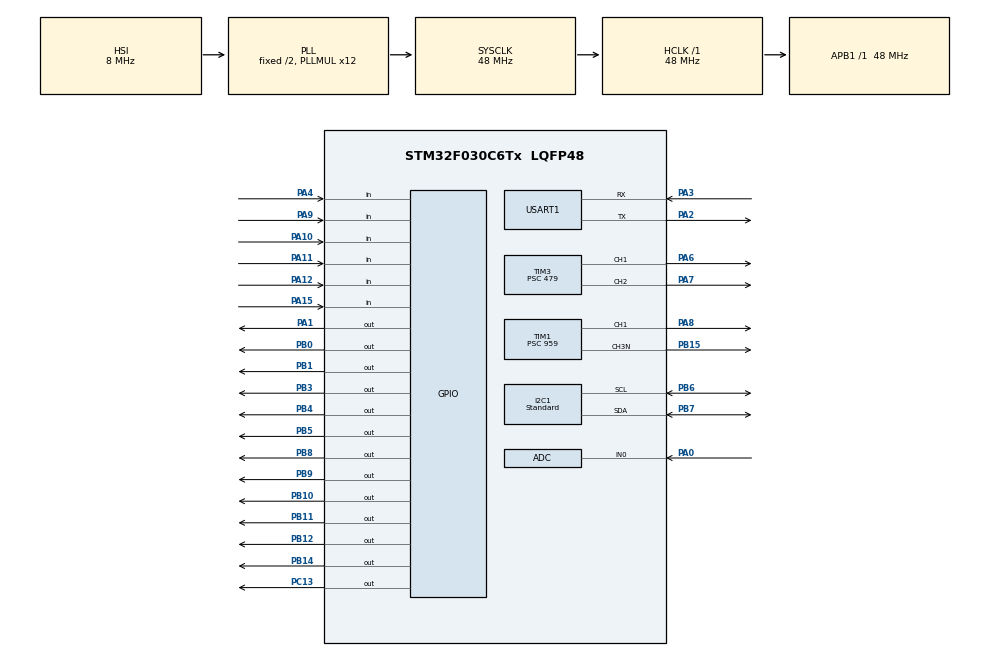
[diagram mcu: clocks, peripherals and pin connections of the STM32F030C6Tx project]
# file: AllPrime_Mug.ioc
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ADC.ClockPrescaler=ADC_CLOCK_ASYNC_DIV1
ADC.ContinuousConvMode=DISABLE
ADC.DiscontinuousConvMode=DISABLE
ADC.EOCSelection=ADC_EOC_SINGLE_CONV
I2C1.I2C_Fall_Time=0
I2C1.I2C_Rise_Time=0
I2C1.I2C_Speed_Mode=I2C_Standard
Mcu.Family=STM32F0
Mcu.Name=STM32F030C6Tx
Mcu.Package=LQFP48
NVIC.TIM14_IRQn=true\:3\:0\:true\:false\:true\:true\:true\:true
NVIC.TIM16_IRQn=true\:1\:0\:true\:false\:true\:true\:true\:true
NVIC.USART1_IRQn=true\:0\:0\:false\:false\:true\:true\:true\:true
PA0.Mode=IN0
PA0.Signal=ADC_IN0
PA1.Signal=GPIO_Output
PA10.Signal=GPIO_Input
PA11.Signal=GPIO_Input
PA12.Signal=GPIO_Input
PA13.Mode=Serial_Wire
PA13.Signal=SYS_SWDIO
PA14.Mode=Serial_Wire
PA14.Signal=SYS_SWCLK
PA15.Signal=GPIO_Input
PA2.Mode=Asynchronous
PA2.Signal=USART1_TX
PA3.Mode=Asynchronous
PA3.Signal=USART1_RX
PA4.Signal=GPIO_Input
PA6.Signal=S_TIM3_CH1
PA7.Signal=S_TIM3_CH2
PA8.Signal=S_TIM1_CH1
PA9.Signal=GPIO_Input
PB0.Signal=GPIO_Output
PB1.Signal=GPIO_Output
PB10.Signal=GPIO_Output
PB11.Signal=GPIO_Output
PB12.Signal=GPIO_Output
PB14.Signal=GPIO_Output
PB15.Mode=PWM Generation3 CH3N
PB15.Signal=TIM1_CH3N
PB3.Signal=GPIO_Output
PB4.Signal=GPIO_Output
PB5.Signal=GPIO_Output
PB6.GPIO_Pu=GPIO_NOPULL
PB6.Mode=I2C
PB6.Signal=I2C1_SCL
PB7.GPIO_Pu=GPIO_PULLUP
PB7.Mode=I2C
PB7.Signal=I2C1_SDA
PB8.Signal=GPIO_Output
PB9.Signal=GPIO_Output
PC13.Signal=GPIO_Output
PC14-OSC32_IN.Mode=LSE-External-Oscillator
PC14-OSC32_IN.Signal=RCC_OSC32_IN
PC15-OSC32_OUT.Mode=LSE-External-Oscillator
PC15-OSC32_OUT.Signal=RCC_OSC32_OUT
PF0-OSC_IN.Mode=HSE-External-Oscillator
PF0-OSC_IN.Signal=RCC_OSC_IN
PF1-OSC_OUT.Mode=HSE-External-Oscillator
PF1-OSC_OUT.Signal=RCC_OSC_OUT
ProjectManager.HeapSize=0x200
ProjectManager.StackSize=0x400
ProjectManager.TargetToolchain=Makefile
RCC.AHBFreq_Value=48000000
RCC.APB1Freq_Value=48000000
RCC.APB1TimFreq_Value=48000000
RCC.HCLKFreq_Value=48000000
RCC.PLLMUL=RCC_PLL_MUL12
RCC.SYSCLKFreq_VALUE=48000000
RCC.SYSCLKSource=RCC_SYSCLKSOURCE_PLLCLK
SH.S_TIM1_CH1.0=TIM1_CH1,PWM Generation1 CH1
SH.S_TIM3_CH1.0=TIM3_CH1,PWM Generation1 CH1
SH.S_TIM3_CH2.0=TIM3_CH2,PWM Generation2 CH2
TIM1.AutoReloadPreload=TIM_AUTORELOAD_PRELOAD_ENABLE
TIM1.Channel-PWM\ Generation1\ CH1=TIM_CHANNEL_1
TIM1.Channel-PWM\ Generation3\ CH3N=TIM_CHANNEL_3
TIM1.Period=1000
TIM1.Prescaler=959
TIM14.AutoReloadPreload=TIM_AUTORELOAD_PRELOAD_ENABLE
TIM14.Period=1000
TIM14.Prescaler=479
TIM16.AutoReloadPreload=TIM_AUTORELOAD_PRELOAD_ENABLE
TIM16.ClockDivision=TIM_CLOCKDIVISION_DIV1
TIM16.Period=100
TIM16.Prescaler=47
TIM3.Channel-PWM\ Generation1\ CH1=TIM_CHANNEL_1
TIM3.Channel-PWM\ Generation2\ CH2=TIM_CHANNEL_2
TIM3.Period=1000
TIM3.Prescaler=479
USART1.VirtualMode-Asynchronous=VM_ASYNC
VP_ADC_TempSens_Input.Mode=IN-TempSens
VP_TIM14_VS_ClockSourceINT.Mode=Enable_Timer
VP_TIM16_VS_ClockSourceINT.Mode=Enable_Timer
VP_TIM1_VS_ClockSourceINT.Mode=Internal
VP_TIM3_VS_ClockSourceINT.Mode=Internal
board=custom

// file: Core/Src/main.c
/* USER CODE BEGIN Header */
/**
  ******************************************************************************
  * @file           : main.c
  * @brief          : Main program body
  ******************************************************************************
  * @attention
  *
  * <h2><center>&copy; Copyright (c) 2021 STMicroelectronics.
  * All rights reserved.</center></h2>
  *
  * This software component is licensed by ST under BSD 3-Clause license,
  * the "License"; You may not use this file except in compliance with the
  * License. You may obtain a copy of the License at:
  *                        opensource.org/licenses/BSD-3-Clause
  *
  ******************************************************************************
  */
/* USER CODE END Header */
#include "main.h"
#include "os.h"

ADC_HandleTypeDef hadc;

I2C_HandleTypeDef hi2c1;

TIM_HandleTypeDef htim1;
TIM_HandleTypeDef htim3;
TIM_HandleTypeDef htim14;
TIM_HandleTypeDef htim16;

UART_HandleTypeDef huart1;

void SystemClock_Config(void);
static void MX_GPIO_Init(void);
static void MX_ADC_Init(void);
static void MX_TIM16_Init(void);
static void MX_I2C1_Init(void);
static void MX_TIM1_Init(void);
static void MX_TIM14_Init(void);
static void MX_TIM3_Init(void);
static void MX_USART1_UART_Init(void);

int main(void)
{

    /* MCU Configuration--------------------------------------------------------*/

    /* Reset of all peripherals, Initializes the Flash interface and the Systick. */
    HAL_Init();

    /* Configure the system clock */
    SystemClock_Config();

    /* Initialize all configured peripherals */
    MX_GPIO_Init();
    MX_ADC_Init();
    MX_TIM16_Init();
 	  MX_I2C1_Init();
 	  MX_TIM1_Init();
  	MX_TIM14_Init();
    MX_TIM3_Init();
    MX_USART1_UART_Init();
    /* USER CODE BEGIN 2 */
    HAL_TIM_Base_Start_IT(&htim1);
    HAL_TIM_Base_Start_IT(&htim3);
    HAL_TIM_Base_Start_IT(&htim14);
    HAL_TIM_Base_Start_IT(&htim16);
    HAL_Delay(1000);
	  Os_Init_Task();
    HAL_TIM_PWM_Start(&htim3,TIM_CHANNEL_1);
    HAL_TIM_PWM_Start(&htim3,TIM_CHANNEL_2);
    HAL_TIM_PWM_Start(&htim1,TIM_CHANNEL_1);
    HAL_TIMEx_PWMN_Start(&htim1,TIM_CHANNEL_3);
    /* USER CODE END 2 */
    /* Infinite loop */

    /* USER CODE BEGIN WHILE */
    while (1)
    {
        Os_Handler();
    }
    /* USER CODE END 3 */
}

void SystemClock_Config(void)
{
  RCC_OscInitTypeDef RCC_OscInitStruct = {0};
  RCC_ClkInitTypeDef RCC_ClkInitStruct = {0};
  RCC_PeriphCLKInitTypeDef PeriphClkInit = {0};

  /** Initializes the RCC Oscillators according to the specified parameters
  * in the RCC_OscInitTypeDef structure.
  */
  RCC_OscInitStruct.OscillatorType = RCC_OSCILLATORTYPE_HSI|RCC_OSCILLATORTYPE_HSI14;
  RCC_OscInitStruct.HSIState = RCC_HSI_ON;
  RCC_OscInitStruct.HSI14State = RCC_HSI14_ON;
  RCC_OscInitStruct.HSICalibrationValue = RCC_HSICALIBRATION_DEFAULT;
  RCC_OscInitStruct.HSI14CalibrationValue = 16;
  RCC_OscInitStruct.PLL.PLLState = RCC_PLL_ON;
  RCC_OscInitStruct.PLL.PLLSource = RCC_PLLSOURCE_HSI;
  RCC_OscInitStruct.PLL.PLLMUL = RCC_PLL_MUL12;
  RCC_OscInitStruct.PLL.PREDIV = RCC_PREDIV_DIV1;
  if (HAL_RCC_OscConfig(&RCC_OscInitStruct) != HAL_OK)
  {
    Error_Handler();
  }

  /** Initializes the CPU, AHB and APB buses clocks
  */
  RCC_ClkInitStruct.ClockType = RCC_CLOCKTYPE_HCLK|RCC_CLOCKTYPE_SYSCLK
                              |RCC_CLOCKTYPE_PCLK1;
  RCC_ClkInitStruct.SYSCLKSource = RCC_SYSCLKSOURCE_PLLCLK;
  RCC_ClkInitStruct.AHBCLKDivider = RCC_SYSCLK_DIV1;
  RCC_ClkInitStruct.APB1CLKDivider = RCC_HCLK_DIV1;

  if (HAL_RCC_ClockConfig(&RCC_ClkInitStruct, FLASH_LATENCY_1) != HAL_OK)
  {
    Error_Handler();
  }
  PeriphClkInit.PeriphClockSelection = RCC_PERIPHCLK_USART1|RCC_PERIPHCLK_I2C1;
  PeriphClkInit.Usart1ClockSelection = RCC_USART1CLKSOURCE_PCLK1;
  PeriphClkInit.I2c1ClockSelection = RCC_I2C1CLKSOURCE_HSI;
  if (HAL_RCCEx_PeriphCLKConfig(&PeriphClkInit) != HAL_OK)
  {
    Error_Handler();
  }
}

static void MX_ADC_Init(void)
{

  ADC_ChannelConfTypeDef sConfig = {0};

  /** Configure the global features of the ADC (Clock, Resolution, Data Alignment and number of conversion)
  */
  hadc.Instance = ADC1;
  hadc.Init.ClockPrescaler = ADC_CLOCK_ASYNC_DIV1;
  hadc.Init.Resolution = ADC_RESOLUTION_12B;
  hadc.Init.DataAlign = ADC_DATAALIGN_RIGHT;
  hadc.Init.ScanConvMode = ADC_SCAN_DIRECTION_FORWARD;
  hadc.Init.EOCSelection = ADC_EOC_SINGLE_CONV;
  hadc.Init.LowPowerAutoWait = DISABLE;
  hadc.Init.LowPowerAutoPowerOff = DISABLE;
  hadc.Init.ContinuousConvMode = DISABLE;
  hadc.Init.DiscontinuousConvMode = DISABLE;
  hadc.Init.ExternalTrigConv = ADC_SOFTWARE_START;
  hadc.Init.ExternalTrigConvEdge = ADC_EXTERNALTRIGCONVEDGE_NONE;
  hadc.Init.DMAContinuousRequests = DISABLE;
  hadc.Init.Overrun = ADC_OVR_DATA_PRESERVED;
  if (HAL_ADC_Init(&hadc) != HAL_OK)
  {
    Error_Handler();
  }

  /** Configure for the selected ADC regular channel to be converted.
  */
  sConfig.Channel = ADC_CHANNEL_0;
  sConfig.Rank = ADC_RANK_CHANNEL_NUMBER;
  sConfig.SamplingTime = ADC_SAMPLETIME_1CYCLE_5;
  if (HAL_ADC_ConfigChannel(&hadc, &sConfig) != HAL_OK)
  {
    Error_Handler();
  }

  /** Configure for the selected ADC regular channel to be converted.
  */
  sConfig.Channel = ADC_CHANNEL_TEMPSENSOR;
  if (HAL_ADC_ConfigChannel(&hadc, &sConfig) != HAL_OK)
  {
    Error_Handler();
  }

}

static void MX_I2C1_Init(void)
{

  hi2c1.Instance = I2C1;
  hi2c1.Init.Timing = 0x2000090E;
  hi2c1.Init.OwnAddress1 = 0;
  hi2c1.Init.AddressingMode = I2C_ADDRESSINGMODE_7BIT;
  hi2c1.Init.DualAddressMode = I2C_DUALADDRESS_DISABLE;
  hi2c1.Init.OwnAddress2 = 0;
  hi2c1.Init.OwnAddress2Masks = I2C_OA2_NOMASK;
  hi2c1.Init.GeneralCallMode = I2C_GENERALCALL_DISABLE;
  hi2c1.Init.NoStretchMode = I2C_NOSTRETCH_DISABLE;
  if (HAL_I2C_Init(&hi2c1) != HAL_OK)
  {
    Error_Handler();
  }

  /** Configure Analogue filter
  */
  if (HAL_I2CEx_ConfigAnalogFilter(&hi2c1, I2C_ANALOGFILTER_ENABLE) != HAL_OK)
  {
    Error_Handler();
  }

  /** Configure Digital filter
  */
  if (HAL_I2CEx_ConfigDigitalFilter(&hi2c1, 0) != HAL_OK)
  {
    Error_Handler();
  }

}

static void MX_TIM1_Init(void)
{

  TIM_ClockConfigTypeDef sClockSourceConfig = {0};
  TIM_MasterConfigTypeDef sMasterConfig = {0};
  TIM_OC_InitTypeDef sConfigOC = {0};
  TIM_BreakDeadTimeConfigTypeDef sBreakDeadTimeConfig = {0};

  htim1.Instance = TIM1;
  htim1.Init.Prescaler = 959;
  htim1.Init.CounterMode = TIM_COUNTERMODE_UP;
  htim1.Init.Period = 1000;
  htim1.Init.ClockDivision = TIM_CLOCKDIVISION_DIV1;
  htim1.Init.RepetitionCounter = 0;
  htim1.Init.AutoReloadPreload = TIM_AUTORELOAD_PRELOAD_ENABLE;
  if (HAL_TIM_Base_Init(&htim1) != HAL_OK)
  {
    Error_Handler();
  }
  sClockSourceConfig.ClockSource = TIM_CLOCKSOURCE_INTERNAL;
  if (HAL_TIM_ConfigClockSource(&htim1, &sClockSourceConfig) != HAL_OK)
  {
    Error_Handler();
  }
  if (HAL_TIM_PWM_Init(&htim1) != HAL_OK)
  {
    Error_Handler();
  }
  sMasterConfig.MasterOutputTrigger = TIM_TRGO_RESET;
  sMasterConfig.MasterSlaveMode = TIM_MASTERSLAVEMODE_DISABLE;
  if (HAL_TIMEx_MasterConfigSynchronization(&htim1, &sMasterConfig) != HAL_OK)
  {
    Error_Handler();
  }
  sConfigOC.OCMode = TIM_OCMODE_PWM1;
  sConfigOC.Pulse = 0;
  sConfigOC.OCPolarity = TIM_OCPOLARITY_HIGH;
  sConfigOC.OCNPolarity = TIM_OCNPOLARITY_HIGH;
  sConfigOC.OCFastMode = TIM_OCFAST_DISABLE;
  sConfigOC.OCIdleState = TIM_OCIDLESTATE_RESET;
  sConfigOC.OCNIdleState = TIM_OCNIDLESTATE_RESET;
  if (HAL_TIM_PWM_ConfigChannel(&htim1, &sConfigOC, TIM_CHANNEL_1) != HAL_OK)
  {
    Error_Handler();
  }
  if (HAL_TIM_PWM_ConfigChannel(&htim1, &sConfigOC, TIM_CHANNEL_3) != HAL_OK)
  {
    Error_Handler();
  }
  sBreakDeadTimeConfig.OffStateRunMode = TIM_OSSR_DISABLE;
  sBreakDeadTimeConfig.OffStateIDLEMode = TIM_OSSI_DISABLE;
  sBreakDeadTimeConfig.LockLevel = TIM_LOCKLEVEL_OFF;
  sBreakDeadTimeConfig.DeadTime = 0;
  sBreakDeadTimeConfig.BreakState = TIM_BREAK_DISABLE;
  sBreakDeadTimeConfig.BreakPolarity = TIM_BREAKPOLARITY_HIGH;
  sBreakDeadTimeConfig.AutomaticOutput = TIM_AUTOMATICOUTPUT_DISABLE;
  if (HAL_TIMEx_ConfigBreakDeadTime(&htim1, &sBreakDeadTimeConfig) != HAL_OK)
  {
    Error_Handler();
  }
  HAL_TIM_MspPostInit(&htim1);

}

static void MX_TIM3_Init(void)
{

  TIM_ClockConfigTypeDef sClockSourceConfig = {0};
  TIM_MasterConfigTypeDef sMasterConfig = {0};
  TIM_OC_InitTypeDef sConfigOC = {0};

  htim3.Instance = TIM3;
  htim3.Init.Prescaler = 479;
  htim3.Init.CounterMode = TIM_COUNTERMODE_UP;
  htim3.Init.Period = 1000;
  htim3.Init.ClockDivision = TIM_CLOCKDIVISION_DIV1;
  htim3.Init.AutoReloadPreload = TIM_AUTORELOAD_PRELOAD_DISABLE;
  if (HAL_TIM_Base_Init(&htim3) != HAL_OK)
  {
    Error_Handler();
  }
  sClockSourceConfig.ClockSource = TIM_CLOCKSOURCE_INTERNAL;
  if (HAL_TIM_ConfigClockSource(&htim3, &sClockSourceConfig) != HAL_OK)
  {
    Error_Handler();
  }
  if (HAL_TIM_PWM_Init(&htim3) != HAL_OK)
  {
    Error_Handler();
  }
  sMasterConfig.MasterOutputTrigger = TIM_TRGO_RESET;
  sMasterConfig.MasterSlaveMode = TIM_MASTERSLAVEMODE_DISABLE;
  if (HAL_TIMEx_MasterConfigSynchronization(&htim3, &sMasterConfig) != HAL_OK)
  {
    Error_Handler();
  }
  sConfigOC.OCMode = TIM_OCMODE_PWM1;
  sConfigOC.Pulse = 0;
  sConfigOC.OCPolarity = TIM_OCPOLARITY_HIGH;
  sConfigOC.OCFastMode = TIM_OCFAST_DISABLE;
  if (HAL_TIM_PWM_ConfigChannel(&htim3, &sConfigOC, TIM_CHANNEL_1) != HAL_OK)
  {
    Error_Handler();
  }
  if (HAL_TIM_PWM_ConfigChannel(&htim3, &sConfigOC, TIM_CHANNEL_2) != HAL_OK)
  {
    Error_Handler();
  }
  HAL_TIM_MspPostInit(&htim3);

}

static void MX_TIM14_Init(void)
{

  htim14.Instance = TIM14;
  htim14.Init.Prescaler = 479;
  htim14.Init.CounterMode = TIM_COUNTERMODE_UP;
  htim14.Init.Period = 1000;
  htim14.Init.ClockDivision = TIM_CLOCKDIVISION_DIV1;
  htim14.Init.AutoReloadPreload = TIM_AUTORELOAD_PRELOAD_ENABLE;
  if (HAL_TIM_Base_Init(&htim14) != HAL_OK)
  {
    Error_Handler();
  }

}

static void MX_TIM16_Init(void)
{

  htim16.Instance = TIM16;
  htim16.Init.Prescaler = 47;
  htim16.Init.CounterMode = TIM_COUNTERMODE_UP;
  htim16.Init.Period = 100;
  htim16.Init.ClockDivision = TIM_CLOCKDIVISION_DIV1;
  htim16.Init.RepetitionCounter = 0;
  htim16.Init.AutoReloadPreload = TIM_AUTORELOAD_PRELOAD_ENABLE;
  if (HAL_TIM_Base_Init(&htim16) != HAL_OK)
  {
    Error_Handler();
  }

}

static void MX_USART1_UART_Init(void)
{

  huart1.Instance = USART1;
  huart1.Init.BaudRate = 38400;
  huart1.Init.WordLength = UART_WORDLENGTH_8B;
  huart1.Init.StopBits = UART_STOPBITS_1;
  huart1.Init.Parity = UART_PARITY_NONE;
  huart1.Init.Mode = UART_MODE_TX_RX;
  huart1.Init.HwFlowCtl = UART_HWCONTROL_NONE;
  huart1.Init.OverSampling = UART_OVERSAMPLING_16;
  huart1.Init.OneBitSampling = UART_ONE_BIT_SAMPLE_DISABLE;
  huart1.AdvancedInit.AdvFeatureInit = UART_ADVFEATURE_NO_INIT;
  if (HAL_UART_Init(&huart1) != HAL_OK)
  {
    Error_Handler();
  }

}

static void MX_GPIO_Init(void)
{
  GPIO_InitTypeDef GPIO_InitStruct = {0};

  /* GPIO Ports Clock Enable */
  __HAL_RCC_GPIOC_CLK_ENABLE();
  __HAL_RCC_GPIOF_CLK_ENABLE();
  __HAL_RCC_GPIOA_CLK_ENABLE();
  __HAL_RCC_GPIOB_CLK_ENABLE();

  /*Configure GPIO pin Output Level */
  HAL_GPIO_WritePin(GPIOC, GPIO_PIN_13, GPIO_PIN_RESET);

  /*Configure GPIO pin Output Level */
  HAL_GPIO_WritePin(GPIOA, GPIO_PIN_1, GPIO_PIN_RESET);

  /*Configure GPIO pin Output Level */
  HAL_GPIO_WritePin(GPIOB, GPIO_PIN_0|GPIO_PIN_1|GPIO_PIN_10|GPIO_PIN_11
                          |GPIO_PIN_12|GPIO_PIN_14|GPIO_PIN_3|GPIO_PIN_4
                          |GPIO_PIN_5|GPIO_PIN_8|GPIO_PIN_9, GPIO_PIN_RESET);

  /*Configure GPIO pin : PC13 */
  GPIO_InitStruct.Pin = GPIO_PIN_13;
  GPIO_InitStruct.Mode = GPIO_MODE_OUTPUT_PP;
  GPIO_InitStruct.Pull = GPIO_NOPULL;
  GPIO_InitStruct.Speed = GPIO_SPEED_FREQ_LOW;
  HAL_GPIO_Init(GPIOC, &GPIO_InitStruct);

  /*Configure GPIO pin : PA1 */
  GPIO_InitStruct.Pin = GPIO_PIN_1;
  GPIO_InitStruct.Mode = GPIO_MODE_OUTPUT_PP;
  GPIO_InitStruct.Pull = GPIO_NOPULL;
  GPIO_InitStruct.Speed = GPIO_SPEED_FREQ_LOW;
  HAL_GPIO_Init(GPIOA, &GPIO_InitStruct);

  /*Configure GPIO pins : PA4 PA9 PA10 PA11
                           PA12 PA15 */
  GPIO_InitStruct.Pin = GPIO_PIN_4|GPIO_PIN_9|GPIO_PIN_10|GPIO_PIN_11
                          |GPIO_PIN_12|GPIO_PIN_15;
  GPIO_InitStruct.Mode = GPIO_MODE_INPUT;
  GPIO_InitStruct.Pull = GPIO_NOPULL;
  HAL_GPIO_Init(GPIOA, &GPIO_InitStruct);

  /*Configure GPIO pins : PB0 PB1 PB10 PB11
                           PB12 PB14 PB3 PB4
                           PB5 PB8 PB9 */
  GPIO_InitStruct.Pin = GPIO_PIN_0|GPIO_PIN_1|GPIO_PIN_10|GPIO_PIN_11
                          |GPIO_PIN_12|GPIO_PIN_14|GPIO_PIN_3|GPIO_PIN_4
                          |GPIO_PIN_5|GPIO_PIN_8|GPIO_PIN_9;
  GPIO_InitStruct.Mode = GPIO_MODE_OUTPUT_PP;
  GPIO_InitStruct.Pull = GPIO_NOPULL;
  GPIO_InitStruct.Speed = GPIO_SPEED_FREQ_LOW;
  HAL_GPIO_Init(GPIOB, &GPIO_InitStruct);

}

void Error_Handler(void)
{
  __disable_irq();
  while (1)
  {
  }
}
